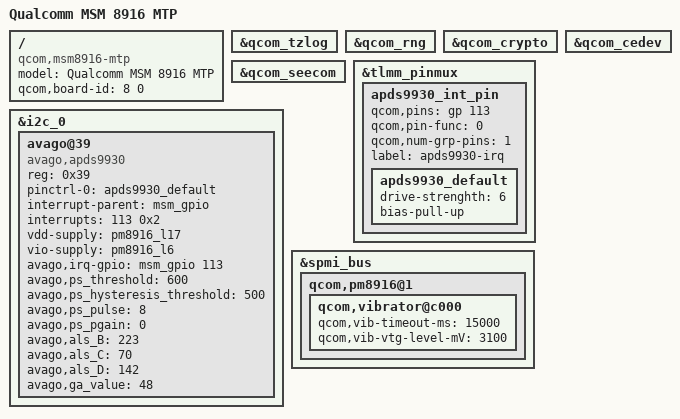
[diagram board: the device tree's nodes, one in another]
/* Copyright (c) 2014, The Linux Foundation. All rights reserved.
*
* This program is free software; you can redistribute it and/or modify
* it under the terms of the GNU General Public License version 2 and
* only version 2 as published by the Free Software Foundation.
*
* This program is distributed in the hope that it will be useful,
* but WITHOUT ANY WARRANTY; without even the implied warranty of
* MERCHANTABILITY or FITNESS FOR A PARTICULAR PURPOSE.  See the
* GNU General Public License for more details.
*/

/dts-v1/;

#include "msm8916-mtp.dtsi"

/ {
	model = "Qualcomm MSM 8916 MTP";
	compatible = "qcom,msm8916-mtp", "qcom,msm8916", "qcom,mtp";
	qcom,board-id = <8 0>;
};

&qcom_tzlog {
	status = "okay";
};

&qcom_rng {
	status = "okay";
};

&qcom_crypto {
	status = "okay";
};

&qcom_cedev {
	status = "okay";
};

&qcom_seecom {
	status = "okay";
};

&tlmm_pinmux {
	apds9930_int_pin {
		qcom,pins = <&gp 113>;
		qcom,pin-func = <0>;
		qcom,num-grp-pins = <1>;
		label = "apds9930-irq";
		apds9930_default: apds9930_default {
			drive-strenghth = <6>;
			bias-pull-up;
		};
	};
};

&i2c_0 { /* BLSP1 QUP2 */
	avago@39 {
		compatible = "avago,apds9930";
		reg = <0x39>;
		pinctrl-names = "default";
		pinctrl-0 = <&apds9930_default>;
		interrupt-parent = <&msm_gpio>;
		interrupts = <113 0x2>;
		vdd-supply = <&pm8916_l17>;
		vio-supply = <&pm8916_l6>;
		avago,irq-gpio = <&msm_gpio 113 0x2>;
		avago,ps_threshold = <600>;
		avago,ps_hysteresis_threshold = <500>;
		avago,ps_pulse = <8>;
		avago,ps_pgain = <0>;
		avago,als_B = <223>;
		avago,als_C = <70>;
		avago,als_D = <142>;
		avago,ga_value = <48>;
	};
};

&spmi_bus {
	qcom,pm8916@1 {
		qcom,vibrator@c000 {
			status = "okay";
			qcom,vib-timeout-ms = <15000>;
			qcom,vib-vtg-level-mV = <3100>;
		};
	};
};
